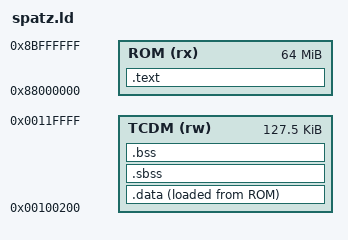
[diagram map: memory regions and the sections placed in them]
/* Generated by pipeline/gen_system_header.py from targets/hetero/system.py.
 * Do not edit: change the machine model and regenerate.
 */
/* Cluster 'spatz': 2 cores, TCDM 0x00100000, code at 0x88000000. */
OUTPUT_ARCH(riscv)
ENTRY(_start)

MEMORY
{
  ROM  (rx) : ORIGIN = 0x88000000, LENGTH = 0x04000000
  TCDM (rw) : ORIGIN = 0x00100200, LENGTH = 0x0001fe00
}

SECTIONS
{
  .text : {
    KEEP(*(.text.init))
    *(.text*)
  } > ROM

  /* Data runs in TCDM but is loaded in main memory; crt0 copies it. The ELF
   * loader cannot burst-write the banked TCDM. */
  . = ALIGN(8);
  .data : {
    __data_start = .;
    *(.rodata*) *(.srodata*)
    . = ALIGN(8);
    *(.data*)
    . = ALIGN(8);
    __global_pointer$ = . + 0x800;
    *(.sdata*)
    . = ALIGN(8);
    __data_end = .;
  } > TCDM AT> ROM

  __data_load_start = LOADADDR(.data);

  . = ALIGN(8);
  __bss_start = .;
  .sbss : { *(.sbss*) } > TCDM
  .bss  : { *(.bss*) *(COMMON) } > TCDM
  . = ALIGN(8);
  __bss_end = .;

  /* Per-core stacks at the top of TCDM: core i runs on
   * (__stack_region + (i + 1) * HES_CLUSTER_STACK_SIZE). */
  __stack_size = 0x1000;
  __stack_region = ORIGIN(TCDM) + LENGTH(TCDM) - 0x2000;

  /* Everything between .bss and the stacks is DMA scratch. */
  . = ALIGN(16);
  __heap_start = .;
  __heap_end = __stack_region;

  ASSERT(__heap_start <= __heap_end,
         "TCDM overflow: cluster data + bss leave no room for the stacks")
}
